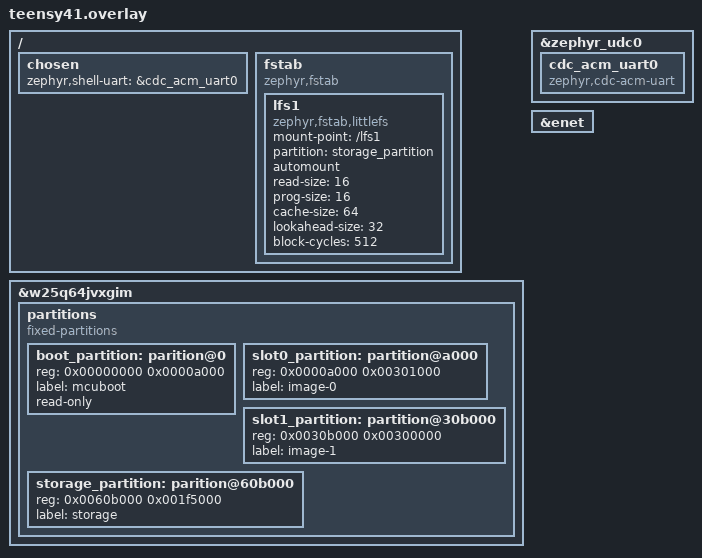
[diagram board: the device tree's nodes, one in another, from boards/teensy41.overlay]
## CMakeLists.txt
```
# Copyright (c) 2022 Peter Maxwell Warasila
#
# SPDX-License-Identifier: MIT

cmake_minimum_required(VERSION 3.20.0)

find_package(Zephyr)
project(my_zephyr_app)

target_sources(app PRIVATE src/main.c)
```

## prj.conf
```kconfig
# Copyright (c) 2022 Peter Maxwell Warasila
#
# SPDX-License-Identifer: MIT

CONFIG_DEBUG_OPTIMIZATIONS=y

# Shell
CONFIG_SHELL=y
CONFIG_LOG=y
CONFIG_KERNEL_SHELL=y

# libc
CONFIG_PICOLIBC=y
CONFIG_PICOLIBC_MODULE=y
CONFIG_PICOLIBC_USE_MODULE=y
CONFIG_PICOLIBC_SPEED_OPTIMIZATIONS=y
CONFIG_PICOLIBC_IO_FLOAT=y

# POSIX
CONFIG_POSIX_API=y
CONFIG_POSIX_CLOCK=y

# Kernel
CONFIG_MAIN_STACK_SIZE=2048

CONFIG_INIT_STACKS=y

# USB Shell
CONFIG_USB_DEVICE_STACK=y
CONFIG_USB_DEVICE_PRODUCT="HackRVA RFID"
CONFIG_USB_DEVICE_INITIALIZE_AT_BOOT=y
CONFIG_UART_LINE_CTRL=y
CONFIG_SHELL_BACKEND_SERIAL_CHECK_DTR=y
CONFIG_SHELL_BACKEND_SERIAL_INIT_PRIORITY=51

# mbedTLS
CONFIG_MBEDTLS=y
CONFIG_MBEDTLS_ZEPHYR_ENTROPY=y
CONFIG_MBEDTLS_SHELL=y

# Networking
CONFIG_NETWORKING=y
CONFIG_NET_L2_ETHERNET=y
CONFIG_NET_IPV6=n
CONFIG_NET_IPV4=y
CONFIG_NET_ARP=y
CONFIG_NET_UDP=y
CONFIG_NET_TCP=y
CONFIG_NET_DHCPV4=y
CONFIG_DNS_RESOLVER=y
CONFIG_NET_SOCKETS=y

CONFIG_SNTP=y

CONFIG_SLIP_STATISTICS=n

CONFIG_NET_MGMT=y
CONFIG_NET_MGMT_EVENT=y

CONFIG_NET_CONFIG_SETTINGS=y
CONFIG_NET_CONFIG_NEED_IPV4=y
CONFIG_NET_CONFIG_CLOCK_SNTP_INIT=y
CONFIG_NET_CONFIG_SNTP_INIT_SERVER="time.nist.gov"
CONFIG_NET_CONFIG_SNTP_INIT_TIMEOUT=10000

CONFIG_NET_LOG=y
CONFIG_NET_SHELL=y
CONFIG_NET_BUF_POOL_USAGE=y
CONFIG_NET_DEBUG_NET_PKT_ALLOC=y
CONFIG_NET_STATISTICS=y

# Flash Storage and Partitions
CONFIG_FLASH=y
CONFIG_FLASH_MAP=y
CONFIG_FLASH_PAGE_LAYOUT=y

# Filesystem
CONFIG_FILE_SYSTEM=y
CONFIG_FILE_SYSTEM_MKFS=y
CONFIG_FILE_SYSTEM_SHELL=y
CONFIG_FILE_SYSTEM_SHELL_TEST_COMMANDS=y

# FATFS
CONFIG_FAT_FILESYSTEM_ELM=y
CONFIG_FS_FATFS_EXFAT=y
CONFIG_FS_FATFS_NUM_FILES=4
CONFIG_FS_FATFS_NUM_DIRS=4
CONFIG_FS_FATFS_LFN=y
CONFIG_FS_FATFS_LFN_MODE_STACK=y
CONFIG_FS_FATFS_MAX_LFN=255
CONFIG_FS_FATFS_CODEPAGE=437
CONFIG_FS_FATFS_MAX_SS=512
CONFIG_FS_FATFS_MIN_SS=512
CONFIG_FS_FATFS_WINDOW_ALIGNMENT=1
CONFIG_FS_FATFS_REENTRANT=y

# littlefs
CONFIG_FILE_SYSTEM_LITTLEFS=y
CONFIG_FS_LITTLEFS_FC_HEAP_SIZE=0
CONFIG_FS_LITTLEFS_HEAP_PER_ALLOC_OVERHEAD_SIZE=32
CONFIG_FS_LITTLEFS_FMP_DEV=y
CONFIG_FS_LITTLEFS_BLK_DEV=n
CONFIG_FS_LITTLEFS_NUM_FILES=4
CONFIG_FS_LITTLEFS_NUM_DIRS=4
CONFIG_FS_LITTLEFS_READ_SIZE=16
CONFIG_FS_LITTLEFS_PROG_SIZE=16
CONFIG_FS_LITTLEFS_CACHE_SIZE=64
CONFIG_FS_LITTLEFS_LOOKAHEAD_SIZE=32
CONFIG_FS_LITTLEFS_BLOCK_CYCLES=512
```

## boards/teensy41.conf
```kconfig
# Copyright (c) 2022 Peter Maxwell Warasila
#
# SPDX-License-Identifer: MIT

CONFIG_ENTROPY_MCUX_TRNG=y
```

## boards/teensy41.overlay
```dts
/*
 * Copyright (c) 2023 Peter Maxwell Warasila
 *
 * SPDX-License-Identifier: MIT
 */

/ {
	chosen {
		zephyr,shell-uart = &cdc_acm_uart0;
	};

	fstab {
		compatible = "zephyr,fstab";
		lfs1: lfs1 {
			compatible = "zephyr,fstab,littlefs";
			mount-point = "/lfs1";
			partition = <&storage_partition>;
			automount;
			read-size = <16>;
			prog-size = <16>;
			cache-size = <64>;
			lookahead-size = <32>;
			block-cycles = <512>;
		};
	};
};

&w25q64jvxgim {
	partitions {
		compatible = "fixed-partitions";
		#address-cells = <0x1>;
		#size-cells = <0x1>;

		boot_partition: parition@0 {
			reg = <0x00000000 0x0000a000>;
			label = "mcuboot";
			read-only;
		};

		/* Slot 0 has an extra sector for mcuboot's move algorithm. */
		slot0_partition: partition@a000 {
			reg = <0x0000a000 0x00301000>;
			label = "image-0";
		};

		slot1_partition: partition@30b000 {
			reg = <0x0030b000 0x00300000>;
			label = "image-1";
		};

		/* No swap using scratch! -PMW */

		storage_partition: parition@60b000 {
			reg = <0x0060b000 0x001f5000>;
			label = "storage";
		};
	};
};

&zephyr_udc0 {
	cdc_acm_uart0: cdc_acm_uart0 {
		compatible = "zephyr,cdc-acm-uart";
	};
};

&enet {
	status = "okay";
};
```

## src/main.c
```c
/*
 * Copyright (c) 2023 Peter Maxwell Warasila
 *
 * SPDX-License-Identifier: MIT
 */

#include <zephyr/kernel.h>
#include <zephyr/drivers/uart.h>

#include <zephyr/usb/usb_device.h>
#include <zephyr/usb/usbd.h>

#include <zephyr/net/net_if.h>
#include <zephyr/net/net_core.h>

int main(int argc, char **argv)
{
	printk("launched!\r\n");

	return 0; 
}
```
